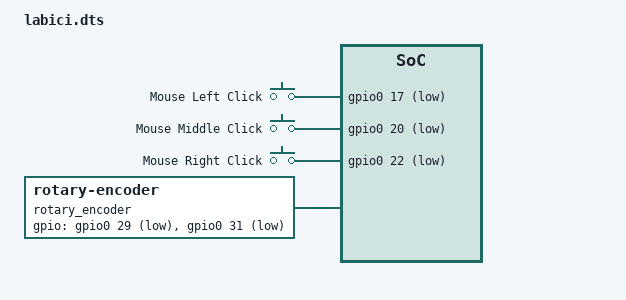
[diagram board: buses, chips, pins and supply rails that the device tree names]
/ {
    compatible = "zmk,shield";

    gpio_keys {
        compatible = "gpio-keys";

        button_left: left {
            gpios = <&gpio0 17 GPIO_ACTIVE_LOW>;
            label = "Mouse Left Click";
            bindings = <&kp BTN1>;
        };

        button_middle: middle {
            gpios = <&gpio0 20 GPIO_ACTIVE_LOW>;
            label = "Mouse Middle Click";
            bindings = <&kp BTN3>;
        };

        button_right: right {
            gpios = <&gpio0 22 GPIO_ACTIVE_LOW>;
            label = "Mouse Right Click";
            bindings = <&kp BTN2>;
        };
    };

    rotary_encoder {
        compatible = "rotary-encoder";
        gpios = <&gpio0 29 GPIO_ACTIVE_LOW>, <&gpio0 31 GPIO_ACTIVE_LOW>;
        steps = <4>;
        bindings = <&mouse_scroll_up>, <&mouse_scroll_down>;
    };
};
